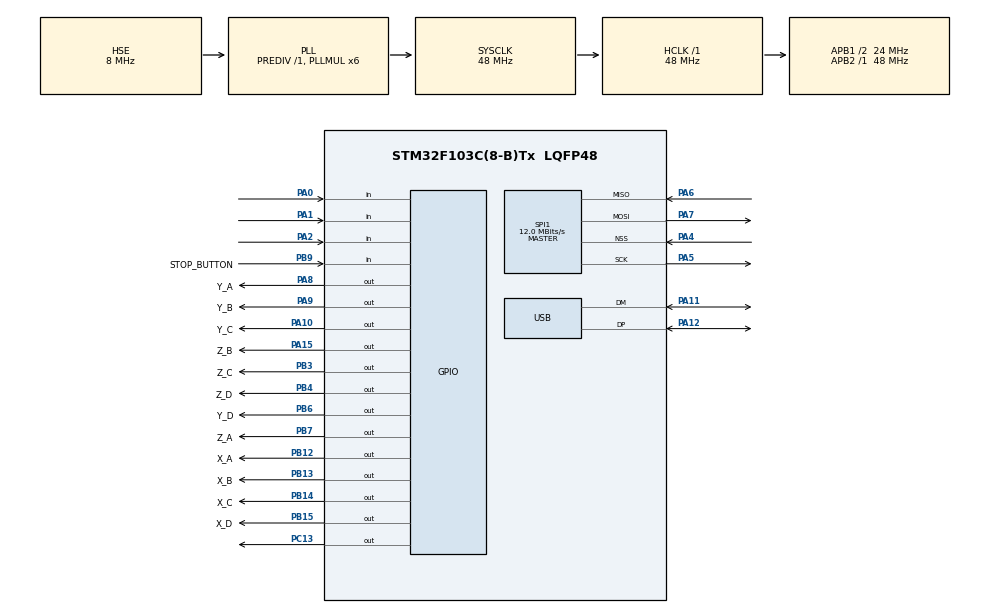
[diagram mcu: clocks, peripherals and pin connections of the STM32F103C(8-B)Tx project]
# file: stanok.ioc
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Mcu.Family=STM32F1
Mcu.Name=STM32F103C(8-B)Tx
Mcu.Package=LQFP48
NVIC.PriorityGroup=NVIC_PRIORITYGROUP_4
NVIC.TIM2_IRQn=true\:0\:0\:false\:false\:true\:true\:true
NVIC.TIM3_IRQn=true\:0\:0\:false\:false\:true\:true\:true
NVIC.TIM4_IRQn=true\:0\:0\:false\:false\:true\:true\:true
NVIC.USB_LP_CAN1_RX0_IRQn=true\:0\:0\:false\:false\:true\:false\:true
PA0-WKUP.GPIO_PuPd=GPIO_PULLDOWN
PA0-WKUP.Signal=GPIO_Input
PA1.GPIO_PuPd=GPIO_PULLDOWN
PA1.Signal=GPIO_Input
PA10.GPIO_Label=Y_C
PA10.PinState=GPIO_PIN_SET
PA10.Signal=GPIO_Output
PA11.Mode=Device
PA11.Signal=USB_DM
PA12.Mode=Device
PA12.Signal=USB_DP
PA13.Mode=Serial_Wire
PA13.Signal=SYS_JTMS-SWDIO
PA14.Mode=Serial_Wire
PA14.Signal=SYS_JTCK-SWCLK
PA15.GPIO_Label=Z_B
PA15.PinState=GPIO_PIN_SET
PA15.Signal=GPIO_Output
PA2.GPIO_PuPd=GPIO_PULLDOWN
PA2.Signal=GPIO_Input
PA4.Mode=NSS_Signal_Hard_Input
PA4.Signal=SPI1_NSS
PA5.Mode=Full_Duplex_Master
PA5.Signal=SPI1_SCK
PA6.Mode=Full_Duplex_Master
PA6.Signal=SPI1_MISO
PA7.Mode=Full_Duplex_Master
PA7.Signal=SPI1_MOSI
PA8.GPIO_Label=Y_A
PA8.PinState=GPIO_PIN_SET
PA8.Signal=GPIO_Output
PA9.GPIO_Label=Y_B
PA9.PinState=GPIO_PIN_SET
PA9.Signal=GPIO_Output
PB12.GPIO_Label=X_A
PB12.PinState=GPIO_PIN_SET
PB12.Signal=GPIO_Output
PB13.GPIO_Label=X_B
PB13.PinState=GPIO_PIN_SET
PB13.Signal=GPIO_Output
PB14.GPIO_Label=X_C
PB14.PinState=GPIO_PIN_SET
PB14.Signal=GPIO_Output
PB15.GPIO_Label=X_D
PB15.PinState=GPIO_PIN_SET
PB15.Signal=GPIO_Output
PB3.GPIO_Label=Z_C
PB3.PinState=GPIO_PIN_SET
PB3.Signal=GPIO_Output
PB4.GPIO_Label=Z_D
PB4.PinState=GPIO_PIN_SET
PB4.Signal=GPIO_Output
PB6.GPIO_Label=Y_D
PB6.PinState=GPIO_PIN_SET
PB6.Signal=GPIO_Output
PB7.GPIO_Label=Z_A
PB7.PinState=GPIO_PIN_SET
PB7.Signal=GPIO_Output
PB9.GPIO_Label=STOP_BUTTON
PB9.Signal=GPIO_Input
PC13-TAMPER-RTC.PinState=GPIO_PIN_SET
PC13-TAMPER-RTC.Signal=GPIO_Output
PD0-OSC_IN.Mode=HSE-External-Oscillator
PD0-OSC_IN.Signal=RCC_OSC_IN
PD1-OSC_OUT.Mode=HSE-External-Oscillator
PD1-OSC_OUT.Signal=RCC_OSC_OUT
ProjectManager.HeapSize=0x200
ProjectManager.StackSize=0x400
ProjectManager.TargetToolchain=STM32CubeIDE
RCC.AHBFreq_Value=48000000
RCC.APB1CLKDivider=RCC_HCLK_DIV2
RCC.APB1Freq_Value=24000000
RCC.APB1TimFreq_Value=48000000
RCC.APB2Freq_Value=48000000
RCC.APB2TimFreq_Value=48000000
RCC.HCLKFreq_Value=48000000
RCC.PLLMUL=RCC_PLL_MUL6
RCC.SYSCLKFreq_VALUE=48000000
RCC.SYSCLKSource=RCC_SYSCLKSOURCE_PLLCLK
RCC.USBFreq_Value=48000000
SPI1.BaudRatePrescaler=SPI_BAUDRATEPRESCALER_4
SPI1.CalculateBaudRate=12.0 MBits/s
SPI1.Direction=SPI_DIRECTION_2LINES
SPI1.Mode=SPI_MODE_MASTER
SPI1.VirtualNSS=VM_NSSHARD
SPI1.VirtualType=VM_MASTER
TIM2.AutoReloadPreload=TIM_AUTORELOAD_PRELOAD_ENABLE
TIM2.Period=9
TIM2.Prescaler=119
USB_DEVICE.CLASS_NAME_FS=CDC
USB_DEVICE.MANUFACTURER_STRING=3D Plotter
USB_DEVICE.PRODUCT_STRING_CDC_FS=3D Plotter
USB_DEVICE.VirtualMode=Cdc
USB_DEVICE.VirtualModeFS=Cdc_FS
VP_CRC_VS_CRC.Mode=CRC_Activate
VP_TIM2_VS_ClockSourceINT.Mode=Internal
VP_TIM3_VS_ClockSourceINT.Mode=Internal
VP_TIM4_VS_ClockSourceINT.Mode=Internal
VP_USB_DEVICE_VS_USB_DEVICE_CDC_FS.Mode=CDC_FS
board=custom

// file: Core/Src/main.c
/* USER CODE BEGIN Header */
/**
  ******************************************************************************
  * @file           : main.c
  * @brief          : Main program body
  ******************************************************************************
  * @attention
  *
  * <h2><center>&copy; Copyright (c) 2020 STMicroelectronics.
  * All rights reserved.</center></h2>
  *
  * This software component is licensed by ST under BSD 3-Clause license,
  * the "License"; You may not use this file except in compliance with the
  * License. You may obtain a copy of the License at:
  *                        opensource.org/licenses/BSD-3-Clause
  *
  ******************************************************************************
  */
/* USER CODE END Header */

#include "main.h"
#include "usb_device.h"

/* USER CODE BEGIN Includes */
#include "timers.h"
#include "usb.h"
#include "drive.h"
//#include "usbd_cdc_if.h"
/* USER CODE END Includes */

CRC_HandleTypeDef hcrc;

SPI_HandleTypeDef hspi1;

TIM_HandleTypeDef htim2;
TIM_HandleTypeDef htim3;
TIM_HandleTypeDef htim4;

void SystemClock_Config(void);
static void MX_GPIO_Init(void);
static void MX_SPI1_Init(void);
static void MX_TIM2_Init(void);
static void MX_TIM3_Init(void);
static void MX_TIM4_Init(void);
static void MX_CRC_Init(void);

int main(void)
{

  /* MCU Configuration--------------------------------------------------------*/

  /* Reset of all peripherals, Initializes the Flash interface and the Systick. */
  HAL_Init();

  /* Configure the system clock */
  SystemClock_Config();

  /* Initialize all configured peripherals */
  MX_GPIO_Init();
  MX_SPI1_Init();
  MX_TIM2_Init();
  MX_TIM3_Init();
  MX_TIM4_Init();
  MX_USB_DEVICE_Init();
  MX_CRC_Init();
  /* USER CODE BEGIN 2 */

  initDrives();
  usbInit();
  /* USER CODE END 2 */

  /* Infinite loop */
  while (1)
  {

    /* USER CODE BEGIN 3 */
	if(incomingMessageFlag==1){
	  	readMessage();
	}
  }
  /* USER CODE END 3 */
}

void SystemClock_Config(void)
{
  RCC_OscInitTypeDef RCC_OscInitStruct = {0};
  RCC_ClkInitTypeDef RCC_ClkInitStruct = {0};
  RCC_PeriphCLKInitTypeDef PeriphClkInit = {0};

  /** Initializes the CPU, AHB and APB busses clocks
  */
  RCC_OscInitStruct.OscillatorType = RCC_OSCILLATORTYPE_HSE;
  RCC_OscInitStruct.HSEState = RCC_HSE_ON;
  RCC_OscInitStruct.HSEPredivValue = RCC_HSE_PREDIV_DIV1;
  RCC_OscInitStruct.HSIState = RCC_HSI_ON;
  RCC_OscInitStruct.PLL.PLLState = RCC_PLL_ON;
  RCC_OscInitStruct.PLL.PLLSource = RCC_PLLSOURCE_HSE;
  RCC_OscInitStruct.PLL.PLLMUL = RCC_PLL_MUL6;
  if (HAL_RCC_OscConfig(&RCC_OscInitStruct) != HAL_OK)
  {
    Error_Handler();
  }
  /** Initializes the CPU, AHB and APB busses clocks
  */
  RCC_ClkInitStruct.ClockType = RCC_CLOCKTYPE_HCLK|RCC_CLOCKTYPE_SYSCLK
                              |RCC_CLOCKTYPE_PCLK1|RCC_CLOCKTYPE_PCLK2;
  RCC_ClkInitStruct.SYSCLKSource = RCC_SYSCLKSOURCE_PLLCLK;
  RCC_ClkInitStruct.AHBCLKDivider = RCC_SYSCLK_DIV1;
  RCC_ClkInitStruct.APB1CLKDivider = RCC_HCLK_DIV2;
  RCC_ClkInitStruct.APB2CLKDivider = RCC_HCLK_DIV1;

  if (HAL_RCC_ClockConfig(&RCC_ClkInitStruct, FLASH_LATENCY_1) != HAL_OK)
  {
    Error_Handler();
  }
  PeriphClkInit.PeriphClockSelection = RCC_PERIPHCLK_USB;
  PeriphClkInit.UsbClockSelection = RCC_USBCLKSOURCE_PLL;
  if (HAL_RCCEx_PeriphCLKConfig(&PeriphClkInit) != HAL_OK)
  {
    Error_Handler();
  }
}

static void MX_CRC_Init(void)
{

  hcrc.Instance = CRC;
  if (HAL_CRC_Init(&hcrc) != HAL_OK)
  {
    Error_Handler();
  }

}

static void MX_SPI1_Init(void)
{

  /* SPI1 parameter configuration*/
  hspi1.Instance = SPI1;
  hspi1.Init.Mode = SPI_MODE_MASTER;
  hspi1.Init.Direction = SPI_DIRECTION_2LINES;
  hspi1.Init.DataSize = SPI_DATASIZE_8BIT;
  hspi1.Init.CLKPolarity = SPI_POLARITY_LOW;
  hspi1.Init.CLKPhase = SPI_PHASE_1EDGE;
  hspi1.Init.NSS = SPI_NSS_HARD_INPUT;
  hspi1.Init.BaudRatePrescaler = SPI_BAUDRATEPRESCALER_4;
  hspi1.Init.FirstBit = SPI_FIRSTBIT_MSB;
  hspi1.Init.TIMode = SPI_TIMODE_DISABLE;
  hspi1.Init.CRCCalculation = SPI_CRCCALCULATION_DISABLE;
  hspi1.Init.CRCPolynomial = 10;
  if (HAL_SPI_Init(&hspi1) != HAL_OK)
  {
    Error_Handler();
  }

}

static void MX_TIM2_Init(void)
{

  TIM_ClockConfigTypeDef sClockSourceConfig = {0};
  TIM_MasterConfigTypeDef sMasterConfig = {0};

  htim2.Instance = TIM2;
  htim2.Init.Prescaler = 119;
  htim2.Init.CounterMode = TIM_COUNTERMODE_UP;
  htim2.Init.Period = 9;
  htim2.Init.ClockDivision = TIM_CLOCKDIVISION_DIV1;
  htim2.Init.AutoReloadPreload = TIM_AUTORELOAD_PRELOAD_ENABLE;
  if (HAL_TIM_Base_Init(&htim2) != HAL_OK)
  {
    Error_Handler();
  }
  sClockSourceConfig.ClockSource = TIM_CLOCKSOURCE_INTERNAL;
  if (HAL_TIM_ConfigClockSource(&htim2, &sClockSourceConfig) != HAL_OK)
  {
    Error_Handler();
  }
  sMasterConfig.MasterOutputTrigger = TIM_TRGO_RESET;
  sMasterConfig.MasterSlaveMode = TIM_MASTERSLAVEMODE_DISABLE;
  if (HAL_TIMEx_MasterConfigSynchronization(&htim2, &sMasterConfig) != HAL_OK)
  {
    Error_Handler();
  }

}

static void MX_TIM3_Init(void)
{

  TIM_ClockConfigTypeDef sClockSourceConfig = {0};
  TIM_MasterConfigTypeDef sMasterConfig = {0};

  htim3.Instance = TIM3;
  htim3.Init.Prescaler = 0;
  htim3.Init.CounterMode = TIM_COUNTERMODE_UP;
  htim3.Init.Period = 0;
  htim3.Init.ClockDivision = TIM_CLOCKDIVISION_DIV1;
  htim3.Init.AutoReloadPreload = TIM_AUTORELOAD_PRELOAD_DISABLE;
  if (HAL_TIM_Base_Init(&htim3) != HAL_OK)
  {
    Error_Handler();
  }
  sClockSourceConfig.ClockSource = TIM_CLOCKSOURCE_INTERNAL;
  if (HAL_TIM_ConfigClockSource(&htim3, &sClockSourceConfig) != HAL_OK)
  {
    Error_Handler();
  }
  sMasterConfig.MasterOutputTrigger = TIM_TRGO_RESET;
  sMasterConfig.MasterSlaveMode = TIM_MASTERSLAVEMODE_DISABLE;
  if (HAL_TIMEx_MasterConfigSynchronization(&htim3, &sMasterConfig) != HAL_OK)
  {
    Error_Handler();
  }

}

static void MX_TIM4_Init(void)
{

  TIM_ClockConfigTypeDef sClockSourceConfig = {0};
  TIM_MasterConfigTypeDef sMasterConfig = {0};

  htim4.Instance = TIM4;
  htim4.Init.Prescaler = 0;
  htim4.Init.CounterMode = TIM_COUNTERMODE_UP;
  htim4.Init.Period = 0;
  htim4.Init.ClockDivision = TIM_CLOCKDIVISION_DIV1;
  htim4.Init.AutoReloadPreload = TIM_AUTORELOAD_PRELOAD_DISABLE;
  if (HAL_TIM_Base_Init(&htim4) != HAL_OK)
  {
    Error_Handler();
  }
  sClockSourceConfig.ClockSource = TIM_CLOCKSOURCE_INTERNAL;
  if (HAL_TIM_ConfigClockSource(&htim4, &sClockSourceConfig) != HAL_OK)
  {
    Error_Handler();
  }
  sMasterConfig.MasterOutputTrigger = TIM_TRGO_RESET;
  sMasterConfig.MasterSlaveMode = TIM_MASTERSLAVEMODE_DISABLE;
  if (HAL_TIMEx_MasterConfigSynchronization(&htim4, &sMasterConfig) != HAL_OK)
  {
    Error_Handler();
  }

}

static void MX_GPIO_Init(void)
{
  GPIO_InitTypeDef GPIO_InitStruct = {0};

  /* GPIO Ports Clock Enable */
  __HAL_RCC_GPIOC_CLK_ENABLE();
  __HAL_RCC_GPIOD_CLK_ENABLE();
  __HAL_RCC_GPIOA_CLK_ENABLE();
  __HAL_RCC_GPIOB_CLK_ENABLE();

  /*Configure GPIO pin Output Level */
  HAL_GPIO_WritePin(GPIOC, GPIO_PIN_13, GPIO_PIN_SET);

  /*Configure GPIO pin Output Level */
  HAL_GPIO_WritePin(GPIOB, X_A_Pin|X_B_Pin|X_C_Pin|X_D_Pin
                          |Z_C_Pin|Z_D_Pin|Y_D_Pin|Z_A_Pin, GPIO_PIN_RESET);

  /*Configure GPIO pin Output Level */
  HAL_GPIO_WritePin(GPIOA, Y_A_Pin|Y_B_Pin|Y_C_Pin|Z_B_Pin, GPIO_PIN_RESET);

  /*Configure GPIO pin : PC13 */
  GPIO_InitStruct.Pin = GPIO_PIN_13;
  GPIO_InitStruct.Mode = GPIO_MODE_OUTPUT_PP;
  GPIO_InitStruct.Pull = GPIO_NOPULL;
  GPIO_InitStruct.Speed = GPIO_SPEED_FREQ_LOW;
  HAL_GPIO_Init(GPIOC, &GPIO_InitStruct);

  /*Configure GPIO pins : PA0 PA1 PA2 */
  GPIO_InitStruct.Pin = GPIO_PIN_0|GPIO_PIN_1|GPIO_PIN_2;
  GPIO_InitStruct.Mode = GPIO_MODE_INPUT;
  GPIO_InitStruct.Pull = GPIO_PULLDOWN;
  HAL_GPIO_Init(GPIOA, &GPIO_InitStruct);

  /*Configure GPIO pins : X_A_Pin X_B_Pin X_C_Pin X_D_Pin
                           Z_C_Pin Z_D_Pin Y_D_Pin Z_A_Pin */
  GPIO_InitStruct.Pin = X_A_Pin|X_B_Pin|X_C_Pin|X_D_Pin
                          |Z_C_Pin|Z_D_Pin|Y_D_Pin|Z_A_Pin;
  GPIO_InitStruct.Mode = GPIO_MODE_OUTPUT_PP;
  GPIO_InitStruct.Pull = GPIO_NOPULL;
  GPIO_InitStruct.Speed = GPIO_SPEED_FREQ_LOW;
  HAL_GPIO_Init(GPIOB, &GPIO_InitStruct);

  /*Configure GPIO pins : Y_A_Pin Y_B_Pin Y_C_Pin Z_B_Pin */
  GPIO_InitStruct.Pin = Y_A_Pin|Y_B_Pin|Y_C_Pin|Z_B_Pin;
  GPIO_InitStruct.Mode = GPIO_MODE_OUTPUT_PP;
  GPIO_InitStruct.Pull = GPIO_NOPULL;
  GPIO_InitStruct.Speed = GPIO_SPEED_FREQ_LOW;
  HAL_GPIO_Init(GPIOA, &GPIO_InitStruct);

  /*Configure GPIO pin : STOP_BUTTON_Pin */
  GPIO_InitStruct.Pin = STOP_BUTTON_Pin;
  GPIO_InitStruct.Mode = GPIO_MODE_INPUT;
  GPIO_InitStruct.Pull = GPIO_NOPULL;
  HAL_GPIO_Init(STOP_BUTTON_GPIO_Port, &GPIO_InitStruct);

}

void Error_Handler(void)
{
}

/************************ (C) COPYRIGHT STMicroelectronics *****END OF FILE****/
